# YTM32B1LE1 register map
Vendor: YTMicro; File version: 1.0
CPU: CM0PLUS r0p1, little endian, MPU, FPU, 2 interrupt priority bits
Registers are 32-bit, read-write, reset 0x0 unless marked. A register's access mark holds for its fields unless they carry their own. Offsets are from the block's base; [hi:lo] are bit positions; {n}, {i} and the like mark numbered series; <NAME> marks a mode.

## EFM — Embedded Flash Module
Base 0x40020000; register names take the prefix EFM_
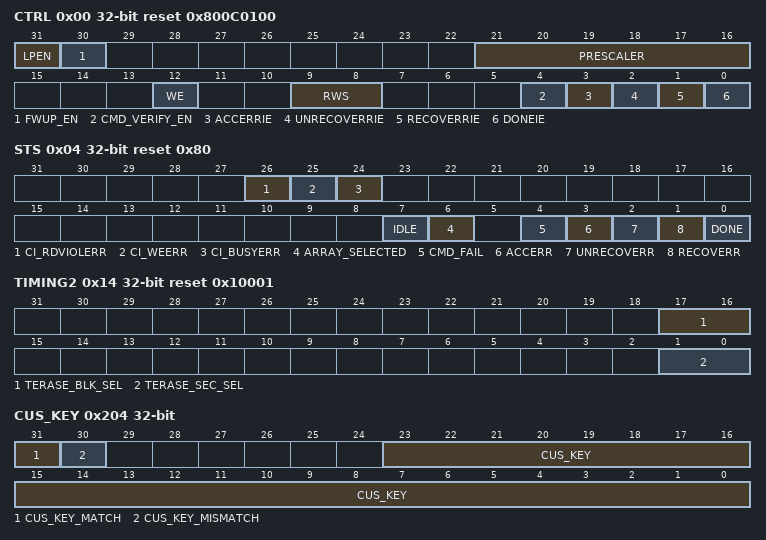
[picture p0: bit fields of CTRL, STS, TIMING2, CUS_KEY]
0x00 CTRL reset 0x800C0100
  [31] LPEN — This LPEN bit determines whether the Flash array will enter low power mode when the MCU send a sleep request. ewline This register bit is reset by System Reset.
    0=Flash will keep active when the MCU send a sleep request; 1=Flash will enter low power mode when the MCU send a sleep request
  [30] FWUP_EN — This FWUP_EN bit determines whether enables fast wake-up of the Flash array. Power consumption of fast wake-up is bigger than normal wake-up. ewline This register bit is reset by System Reset.
    0=Flash wake-up time from Deep Standby mode is 20us; 1=Flash wake-up time from Deep Standby mode is 10us
  [21:16] PRESCALER — These PRESCALER bits are used for EFM operation time control. ewline Please use the following equation to calculate the PRESCALER value: ewline PRESCALER = Slow bus clock frequency / 2 ewline Round up if not divisible. ewline The unit of Slow bus clock frequency is Mhz. ewline For example, if Slow bus clock frequency is 40Mhz, PRESCALER value should be 20. ewline Please re-configure PRESCALER once the frequency is changed. ewline This register bit is reset by System Reset.
  [12] WE — This WE bit determines whether Flash is writable. Write Flash when WE is 0 causes bus error and STS[CI_WEERR] flag is set at the same time. ewline This register bit is reset by System Reset.
    0=Disable Flash write; 1=Enable Flash write
  [9:8] RWS
    0=Valid value for core clk <= 48Mhz; 1=Valid value for core clk <= 48Mhz; 2=Valid value for core clk <= 64Mhz; 3=Valid value for core clk <= 80Mhz
  [4] CMD_VERIFY_EN — This CMD_VERIFY_EN bit determines whether to do verify read after erase or program operation during executing a command. ewline - After each program cycle, if CMD_VERIFY_EN=1, EFM should read the programmed address and compare the read data to program data, if not equal, set STS[CMD_FAIL] flag to 1. ewline - After each erase cycle, if CMD_VERIFY_EN=1, EFM should read the erased addresses and compare read data with FF, if read data are not all FF, set STS[CMD_FAIL] flag to 1. ewline This register bit is reset by System Reset.
    0=Disable verify read after erase or program cycle; 1=Enable verify read after erase or program cycle
  [3] ACCERRIE — This ACCERRIE bit determines whether the interrupt will be generated when STS[ACCERR] flag is asserted. ewline This register bit is reset by System Reset.
    0=Don't generate interrupt when STS[ACCERR] flag is asserted; 1=Generate interrupt when STS[ACCERR] flag is asserted
  [2] UNRECOVERRIE — This UNRECOVERRIE bit determines whether the interrupt will be generated when STS[UNRECOVERR] flag is asserted. ewline This register bit is reset by System Reset.
    0=Don't generate interrupt when STS[UNRECOVERR] flag is asserted; 1=Generate interrupt when STS[UNRECOVERR] flag is asserted
  [1] RECOVERRIE — This RECOVERRIE bit determines whether the interrupt will be generated when STS[RECOVERR] flag is asserted. ewline This register bit is reset by System Reset.
    0=Don't generate interrupt when STS[RECOVER] flag is asserted; 1=Generate interrupt when STS[RECOVERR] flag is asserted
  [0] DONEIE — This DONEIE bit determines whether the interrupt will be generated when DONE flag is asserted. ewline This register bit is reset by System Reset.
    0=Don't generate interrupt when STS[DONE] flag is asserted; 1=Generate interrupt when STS[DONE] flag is asserted
0x04 STS reset 0x80
  [26] CI_RDVIOLERR — This CI_RDVIOLERR bit indicates whether a read violation error is detected. Please check this bit after bus error. ewline Read violation error includes below scenarios: ewline - Read CUS_NVR sector when CUS_KEY is not set. ewline ewline This register bit is reset by System Reset.
  [25] CI_WEERR — Try to write Flash array when CTRL[WE] is disabled will cause bus error and set CI_WEERR flag. ewline This register bit is reset by System Reset.
  [24] CI_BUSYERR — Try to access Flash array when CTRL[IDLE] is 0 will cause bus error and set CI_BUSYERR flag. ewline This register bit is reset by System Reset.
  [7] IDLE ro — This IDLE bit indicates whether EFM is busy executing a command. ewline This register bit is reset by System Reset.
    0=EFM is excuting a command; 1=EFM is idle
  [6] ARRAY_SELECTED ro — Software should write target array address before launching a command. The write operation will set ARRAY_SELECTED flag after several cycles. ewline This register bit is reset by System Reset. ewline ote{Launching command when ARRAY_SELECTED=1 avoid access error caused by non-sequential scheduling of instructions.}
    0=The target Flash array is not selected. EFM is not ready to launch a command.; 1=The target Flash array is selected. EFM is ready to launch a command.
  [4] CMD_FAIL — This CMD_FAIL bit indicates whether the current command is failed. ewline Command failure includes below scenarios: ewline - Read check before a program cycle failed if data and ECC bits are not all FF. ewline - Verify check after a erase cycle failed if data and ECC bits are not cleared to all FF. ewline - Verify check after a program cycle failed if program data not equal to read data. ewline This register bit is reset by System Reset.
  [3] ACCERR — This ACCERR bit indicates whether an access error is detected. This flag is set after write CMD. When an access error occurred, the command is not launched. ewline Access error scenarios refer to \hyperref[flash-abnormal-operation]{Flash Abnormal Operation}. ewline This register bit is reset by System Reset.
    0=Access error is not detected; 1=Access error is detected
  [2] UNRECOVERR — This UNRECOVERR bit indicates whether a 2-bit ECC error is detected during Flash read. ewline This register bit is reset by Power-on Reset.
    0=No un-recovery ECC error is detected; 1=2-bit ECC error is detected
  [1] RECOVERR — This RECOVERR bit indicates whether a 1-bit ECC error is detected during Flash read. ewline This register bit is reset by Power-on Reset.
    0=No recovery ECC error is detected; 1=1-bit ECC error is detected
  [0] DONE — This DONE bit indicates whether the current command is completed. ewline This register bit is reset by System Reset.
    0=Current command is in progress; 1=Current command is completed
0x08 CMD
  [7:0] CMD — These CMD bits determine which commands are available. Write valid command code to CMD to launch a command. Refer to table \hyperref[efm-commands]{EFM commands} for command code. ewline This register bit is reset by System Reset.
0x0C CMD_PROT
  [31:0] CMD_PROT — These CMD_PROT is used to disable commands. ewline Once bit CMD_PROTn is set HIGH, its corresponding command is disabled. Refer to \hyperref[efm-commands]{EFM commands} table for the map between commands and CMD_PROT bits ewline This register bit is reset by System Reset.
0x10 TIMING1 reset 0x1
  [1:0] TPROG_SEL — These TPROG_SEL bits indicate the program pulse time. ewline The valid program pulse time is from 5us to 6.5us. Specific program time is decided by TPROG_SEL by fixed step. ewline For example, if TPROG_SEL is 01, the Flash array program pulse time is 5.5us. ewline This register bit is reset by System Reset.
    0=Flash array program pulse time is 5us; 1=Flash array program pulse time is 5.5us; 2=Flash array program pulse time is 6us; 3=Flash array program pulse time is 6.5us
0x14 TIMING2 reset 0x10001
  [17:16] TERASE_BLK_SEL — These TERASE_BLK_SEL bits indicate the block erase pulse times. ewline The valid block erase pulse time is from 30ms to 40ms. Specific block erase time is decided by TERASE_BLK_SEL. ewline For example, if TERASE_BLK_SEL value is 01, the Flash array block erase pulse time is 34ms. ewline This register bit is reset by System Reset. ote{Please set TERASE_BLK_SEL register to valid value before send EFM command ERASE_BLOCK or core debugger mass erase request.}
    0=Flash array block erase pulse time is 31ms; 1=Flash array block erase pulse time is 34ms; 2=Flash array block erase pulse time is 36ms; 3=Flash array block erase pulse time is 39ms
  [1:0] TERASE_SEC_SEL — These TERASE_SEC_SEL bits indicate the sector erase pulse times. ewline The valid sector erase pulse time is from 2ms to 3ms. Specific sector erase time is decided by TERASE_SEC_SEL. ewline For example, if TERASE_SEC_SEL value is 01, the Flash array sector erase pulse time is 2.4ms. ewline This register bit is reset by System Reset. ote{Please set TERASE_SEC_SEL register to valid value before send ERASE_SECTOR command.}
    0=Flash array sector erase pulse time is 2.1ms; 1=Flash array sector erase pulse time is 2.4ms; 2=Flash array sector erase pulse time is 2.6ms; 3=Flash array sector erase pulse time is 2.9ms
0x20 ERR_INJECT_CTRL
  [31:30] ECCERR_INJ_EN — Set this ECCERR_INJ_EN bits while cause 1-bit/ 2-bit ECC error for all Flash reading. ewline This register bit is reset by System Reset.
    0=00b (Disable ECC error inject .); 1=01b (Inject 1-bit ECC error for any address.); 2=10b (Inject 1-bit ECC error for any address.); 3=11b (Inject 2-bit ECC error for any address.)
0x24 ADDR_PROT0 reset 0xFFFFFFFF
  [31:0] ADDR_PROT — The address area of each PFlash is divided into 32 regions. Each region is protected by one bit of ADDR_PROT. The address area of each region is 4KB. ewline If any bit is set to 0, its corresponding region is under protection (read only). ewline EFM hardware initialization flow (STS[IDLE]=0) will load ADDR_PROT registers with initial values from CUS_NVR array if the CUS_NVR has programmed with initial ADDR_PROT values and tag. ewline After EFM hardware initialization done (STS[IDLE]=1), software can write 0 to value 1 bit of ADDR_PROT, but can not write 1 to value 0 bit. ewline This register bit is reset by System Reset.
0x30 ECCERR_ADDR reset 0xFFFFFFFF
  [31:0] ERR_FLASH_ADDR ro — These bits records the first detected ECC error address. Followed ECC error addresses are not recorded. ewline This register bit is reset by Power-on Reset. ewline When detecting an ECC error, hardware will set ECC error flag (RECOVERR or UNRECOVERR) and record information about error Flash address and error array. Read ECCERR_ADDR can get SOC address of the recorded ECC error. ewline ECCERR_ADDR is cleared by writing 1 to the corresponding error flag. For example, if ECCERR_ADDR records UNRECOVERR address information, only write 1 to UNRECOVERR can clear ECCERR_ADDR, writing 1 to RECOVERR can not clear ECCERR_ADDR. ewline ECCERR_ADDR is aligned to 8Byte because a FLash read get a 64-bit page data. When recorded an ECC error address in ECCERR_ADDR, any bus read of Flash address located in ECCERR_ADDR~(ECCERR_ADDR+0x7) will get ECC error too. ewline
0x34 ECCERR_CNT
  [13:0] ECCERR_CNT ro — These ECCERR_CNT bits record 1-bit and 2-bit ECC errors. ewline This register bit is reset by Power-on Reset.
0x200 CMD_UNLOCK wo
  [31:0] CMD_UNLOCK_KEY — Please write 0xfd9573f5 before launching a command
0x204 CUS_KEY
  [31] CUS_KEY_MATCH ro — This CUS_KEY_MATCH bit indicates whether Customer Key is matched. ewline Write CUS_KEY with correct value when both CUS_KEY_MATCH and CUS_KEY_MISMATCH are low will set this flag high. ewline When CUS_KEY_MATCH is high, write error value to CUS_KEY will clear this flag. ewline When CUS_KEY_MISMATCH is high, this flag is low until a reset happened. ewline This register bit is reset by System Reset.
    0=Customer Key is not matched; 1=Customer Key is matched
  [30] CUS_KEY_MISMATCH ro — This CUS_KEY_MISMATCH bit indicates whether Customer Key is mis-matched. ewline Write CUS_KEY with error value when both CUS_KEY_MATCH and CUS_KEY_MISMATCH are low will set this bit to high. ewline When CUS_KEY_MISMATCH is high, CUS_KEY configuration is blocked. ewline This register bit is reset by Power-on Reset.
    0=Customer Key is matched; 1=Customer Key is not matched
  [23:0] CUS_KEY wo — Following are Customer Key protected operations, please write CUS_KEY with correct value before doing these operations: ewline - Read or erase or program CUS_NVR ewline - Erase HCU_NVR array if it is exist ewline Default Customer Key value is 0x4DFF32 and the Customer Key can be re-defined by programming the first address of CUS_NVR, it will be effective after EFM is reset.
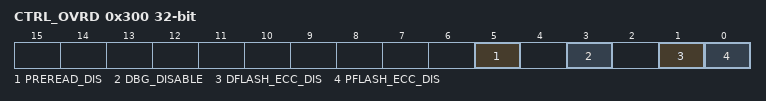
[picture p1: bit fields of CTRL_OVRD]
0x300 CTRL_OVRD
  [5] PREREAD_DIS wo — EFM will read Flash and check if the target address is erased empty before send a program pulse. If target address is not erased empty, no program pulse is send to Flash. ewline To inject ECC error into Flash array. Software should set PREREAD_DIS and then program a Flash word twice with different data. ewline This register bit is protected by cus_key. ewline This register bit is reset by System Reset.
    0=Pre-read function is enabled before send a program pulse; 1=Pre-read function is disabled before send a program pulse
  [3] DBG_DISABLE wo — This bit determines whether the debugger is disabled. ewline This register bit is protected by cus_key. ewline This register bit is reset by System Reset.
    0=Debugger is enabled; 1=Debugger is disabled
  [1] DFLASH_ECC_DIS wo — This bit determines whether DFlash array data bus ECC Decode/Encode is disabled. ewline This register bit is protected by cus_key. ewline This register bit is reset by Power-on Reset.
  [0] PFLASH_ECC_DIS wo — This bit determines whether PFlash array data bus ECC Decode is disabled. Each bit controls the ECC calculation of each block. ewline This register bit is protected by cus_key. ewline This register bit is reset by Power-on Reset.
